AUTOSAR XML (schema 4-2-1)
package /CanSystem
  system CanSystem
    5 x system mapping:
      EBConnectionEditorMappings
        data-mappings:
          sender-receiver-to-signal-group-mapping={data-element=TopLevelComposition.P_E2E_SafeData.E2EProt_Data, signal-group=sigGroup_E2EProt_DataOut, type-mapping=sender-rec-record-type-mapping=record-element-mappings=[{implementation-record-element=SafetyE2E_Data, system-signal=SysSig_E2EProt_DataOut}, {implementation-record-element=SafetyE2E_Data_CRC, system-signal=SysSig_E2EProt_DataOut_CRC}, {implementation-record-element=SafetyE2E_Data_SQC_Counter, system-signal=SysSig_E2EProt_DataOut_SQC_Counter}]}
          sender-receiver-to-signal-group-mapping={data-element=TopLevelComposition.R_E2E_SafeData.E2EProt_Data, signal-group=sigGroup_E2EProt_DataIn, type-mapping=sender-rec-record-type-mapping=record-element-mappings=[{implementation-record-element=SafetyE2E_Data, system-signal=SysSig_E2EProt_DataIn}, {implementation-record-element=SafetyE2E_Data_CRC, system-signal=SysSig_E2EProt_DataIn_CRC}, {implementation-record-element=SafetyE2E_Data_SQC_Counter, system-signal=SysSig_E2EProt_DataIn_SQC_Counter}]}
          sender-receiver-to-signal-mapping={data-element=TopLevelComposition.R_CounterIn.CounterValue, system-signal=CounterIn}
          sender-receiver-to-signal-mapping={data-element=TopLevelComposition.R_CounterIn_FD.CounterValue_FD, system-signal=CounterIn_CAN_FD}
        sw-mappings:
          swc to ecu mapping EBConnectionEditorSwcMappings: ecu-instance=EcuTestNode
            component:
              TopLevelComposition.NvM_Prototype
              TopLevelComposition.Dcm_Prototype
              TopLevelComposition.Dem_Prototype
              TopLevelComposition.BswM_Prototype
              TopLevelComposition.ComM_Prototype
              TopLevelComposition.DevelopmentErrorTracer_Prototype
              TopLevelComposition.SecOC_Prototype
              TopLevelComposition.SWC_E2ESafety
              TopLevelComposition.SWC_SPI_Prototype
      EBConnectionEditorMappings_0_SecuredDataOut: sender-receiver-to-signal-mapping{data-element=TopLevelComposition.P_SecureData.CounterValue, system-signal=SecuredDataOut}
      EBConnectionEditorMappings_1_SecuredDataIn: sender-receiver-to-signal-mapping{data-element=TopLevelComposition.R_SecureData.CounterValue, system-signal=SecuredDataIn}
      EBConnectionEditorMappings_2_CounterOut: sender-receiver-to-signal-mapping{data-element=TopLevelComposition.P_CounterOut.CounterValue, system-signal=CounterOut}
      EBConnectionEditorMappings_3_CounterOut_CAN_FD: sender-receiver-to-signal-mapping{data-element=TopLevelComposition.P_CounterOut_FD.CounterValue_FD, system-signal=CounterOut_CAN_FD}
package /DemoApplication/SwComponentTypes
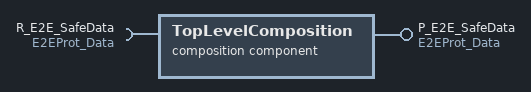
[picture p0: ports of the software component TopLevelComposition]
  composition sw component type TopLevelComposition
    provide port P_E2E_SafeData: provided-interface=E2EProt_Data
    require port R_E2E_SafeData: required-interface=E2EProt_Data
    9 x component:
      BswM_Prototype: type=BswM
      ComM_Prototype: type=ComM
      Dcm_Prototype: type=Dcm
      Dem_Prototype: type=Dem
      DevelopmentErrorTracer_Prototype: type=DevelopmentErrorTracer
      NvM_Prototype: type=NvM
      SWC_E2ESafety: type=SWC_E2ESafety
      SWC_SPI_Prototype: type=SWC_SPI
      SecOC_Prototype: type=SecOC
    connect BswM_Prototype.BswM_ModeRequestPort_BswMRteModeRequestPort_AppStateMode -> SWC_AppStateHandler.AppStateRequest
    connect SWC_AppStateHandler.AppState -> BswM_Prototype.ModeNotificationPort_BswM_ModeReqPort_AppState
    connect BswM_Prototype.BswM_ModeSwitchPort_BswM_SwitchPort_Rte -> SWC_CyclicCounter.ModeSwitchPort_BSWM_COMBINEDACTION_BswMMode_PortInterfaces_BswMMode
    connect DevelopmentErrorTracer_Prototype.DS_SWC_0 -> SWC_CyclicCounter.R_CyclicCounterDet
    connect NvM_Prototype.PS_NvM_BLOCK_voltage -> SWC_SPI_Prototype.PS_NvM_Block_voltage
    connect NvM_Prototype.PS_PersistentCounterValue -> SWC_CyclicCounter.PS_PersistentCounterValue
    delegate SWC_CyclicCounter.P_CounterOut_FD <-> outer port P_CounterOut_FD
    delegate SWC_E2ESafety.P_E2E_SafeData <-> outer port P_E2E_SafeData
    connect SWC_CyclicCounter.P_EchoCalc_FD -> SWC_ModifyEcho.R_EchoResult_FD
    delegate SWC_Secured.P_SecuredData <-> outer port P_SecureData
    connect SWC_IoHwAbs.Pp_AdcValue -> SWC_SPI_Prototype.Rp_AdcValue
    delegate SWC_E2ESafety.R_E2E_SafeData <-> outer port R_E2E_SafeData
    delegate SWC_Secured.R_SecuredData <-> outer port R_SecureData
